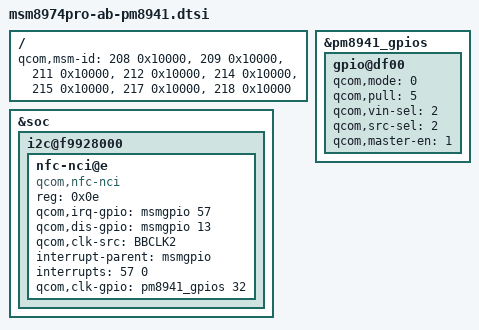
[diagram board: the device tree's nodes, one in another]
/* Copyright (c) 2013-2014, The Linux Foundation. All rights reserved.
 *
 * This program is free software; you can redistribute it and/or modify
 * it under the terms of the GNU General Public License version 2 and
 * only version 2 as published by the Free Software Foundation.
 *
 * This program is distributed in the hope that it will be useful,
 * but WITHOUT ANY WARRANTY; without even the implied warranty of
 * MERCHANTABILITY or FITNESS FOR A PARTICULAR PURPOSE.  See the
 * GNU General Public License for more details.
 */

#include "msm8974pro-pm8941.dtsi"

/ {
	qcom,msm-id = <208 0x10000>,
		      <209 0x10000>,
		      <211 0x10000>,
		      <212 0x10000>,
		      <214 0x10000>,
		      <215 0x10000>,
		      <217 0x10000>,
		      <218 0x10000>;
};

&soc {
	i2c@f9928000 { /* BLSP1 QUP6 */
		nfc-nci@e {
			compatible = "qcom,nfc-nci";
			reg = <0x0e>;
			qcom,irq-gpio = <&msmgpio 57 0x00>;
			qcom,dis-gpio = <&msmgpio 13 0x00>;
			qcom,clk-src = "BBCLK2";
			interrupt-parent = <&msmgpio>;
			interrupts = <57 0>;
			qcom,clk-gpio = <&pm8941_gpios 32 0>;
		};
	};
};

&pm8941_gpios {
	gpio@df00 {
		/* NFC clk request */
		qcom,mode = <0>;                /* QPNP_PIN_MODE_DIG_IN */
		qcom,pull = <5>;                /* QPNP_PIN_PULL_NO */
		qcom,vin-sel = <2>;             /* QPNP_PIN_VIN2 */
		qcom,src-sel = <2>;             /* QPNP_PIN_SEL_FUNC_1 */
		qcom,master-en = <1>;
	};
};
